# STM32L15xC register map
File version: 1.0
CPU: 
Registers are 32-bit, read-write, reset 0x0 unless marked. A register's access mark holds for its fields unless they carry their own. Offsets are from the block's base; [hi:lo] are bit positions; {n}, {i} and the like mark numbered series.

## SPI1 — Serial peripheral interface
Base 0x40013000
Same registers: SPI2 0x40003800, SPI3 0x40003C00
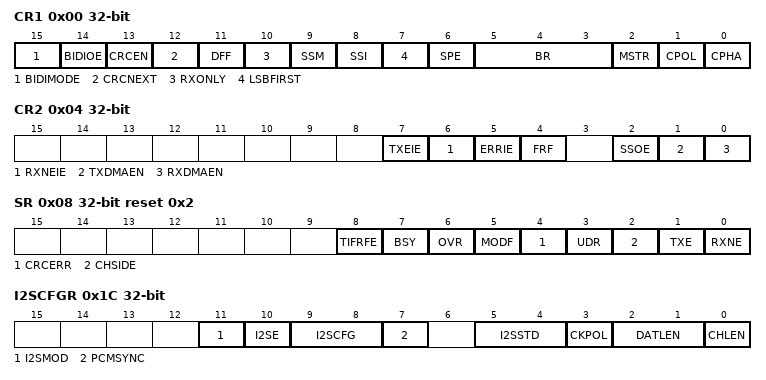
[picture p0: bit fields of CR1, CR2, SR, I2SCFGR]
0x00 CR1 — control register 1
  [15] BIDIMODE — Bidirectional data mode enable
  [14] BIDIOE — Output enable in bidirectional mode
  [13] CRCEN — Hardware CRC calculation enable
  [12] CRCNEXT — CRC transfer next
  [11] DFF — Data frame format
  [10] RXONLY — Receive only
  [9] SSM — Software slave management
  [8] SSI — Internal slave select
  [7] LSBFIRST — Frame format
  [6] SPE — SPI enable
  [5:3] BR — Baud rate control
  [2] MSTR — Master selection
  [1] CPOL — Clock polarity
  [0] CPHA — Clock phase
0x04 CR2 — control register 2
  [7] TXEIE — Tx buffer empty interrupt enable
  [6] RXNEIE — RX buffer not empty interrupt enable
  [5] ERRIE — Error interrupt enable
  [4] FRF — Frame format
  [2] SSOE — SS output enable
  [1] TXDMAEN — Tx buffer DMA enable
  [0] RXDMAEN — Rx buffer DMA enable
0x08 SR access per field reset 0x2 — status register
  [8] TIFRFE ro — TI frame format error
  [7] BSY ro — Busy flag
  [6] OVR ro — Overrun flag
  [5] MODF ro — Mode fault
  [4] CRCERR rw — CRC error flag
  [3] UDR ro — Underrun flag
  [2] CHSIDE ro — Channel side
  [1] TXE ro — Transmit buffer empty
  [0] RXNE ro — Receive buffer not empty
0x0C DR — data register
  [15:0] DR — Data register
0x10 CRCPR reset 0x7 — CRC polynomial register
  [15:0] CRCPOLY
0x14 RXCRCR ro — RX CRC register
  [15:0] RxCRC
0x18 TXCRCR ro — TX CRC register
  [15:0] TxCRC
0x1C I2SCFGR — I2S configuration register
  [11] I2SMOD — I2S mode selection
  [10] I2SE — I2S Enable
  [9:8] I2SCFG — I2S configuration mode
  [7] PCMSYNC — PCM frame synchronization
  [5:4] I2SSTD — I2S standard selection
  [3] CKPOL — Steady state clock polarity
  [2:1] DATLEN — Data length to be transferred
  [0] CHLEN — Channel length (number of bits per audio channel)
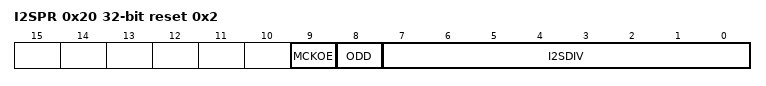
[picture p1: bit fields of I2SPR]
0x20 I2SPR reset 0x2 — I2S prescaler register
  [9] MCKOE — Master clock output enable
  [8] ODD — Odd factor for the prescaler
  [7:0] I2SDIV — I2S Linear prescaler

## SYSCFG — System configuration controller
Base 0x40010000
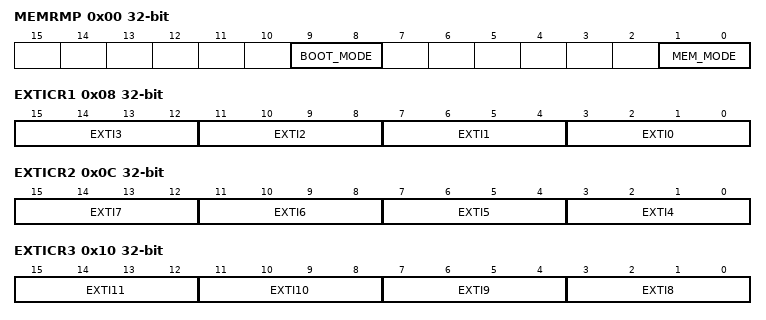
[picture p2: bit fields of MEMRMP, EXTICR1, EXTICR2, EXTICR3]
0x00 MEMRMP access per field — memory remap register
  [9:8] BOOT_MODE ro, [1:0] MEM_MODE rw
0x04 PMC — peripheral mode configuration register
  [0] USB_PU — USB pull-up
0x08 EXTICR1 — external interrupt configuration register 1
  [4n+3:4n] EXTI{n} (n=0..3) — EXTI x configuration (x = 0 to 3)
0x0C EXTICR2 — external interrupt configuration register 2
  [4n-13:4n-16] EXTI{n} (n=4..7) — EXTI x configuration (x = 4 to 7)
0x10 EXTICR3 — external interrupt configuration register 3
  [15:12] EXTI11 — EXTI x configuration (x = 8 to 11)
  [11:8] EXTI10
  [7:4] EXTI9 — EXTI x configuration (x = 8 to 11)
  [3:0] EXTI8 — EXTI x configuration (x = 8 to 11)
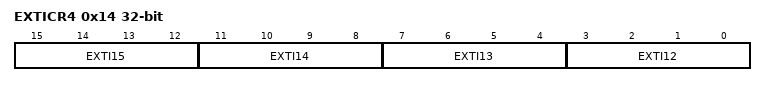
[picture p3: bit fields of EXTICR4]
0x14 EXTICR4 — external interrupt configuration register 4
  [15:12] EXTI15 — EXTI x configuration (x = 12 to 15)
  [11:8] EXTI14
  [7:4] EXTI13
  [3:0] EXTI12

## TIM10 — General-purpose timers
Base 0x40010C00
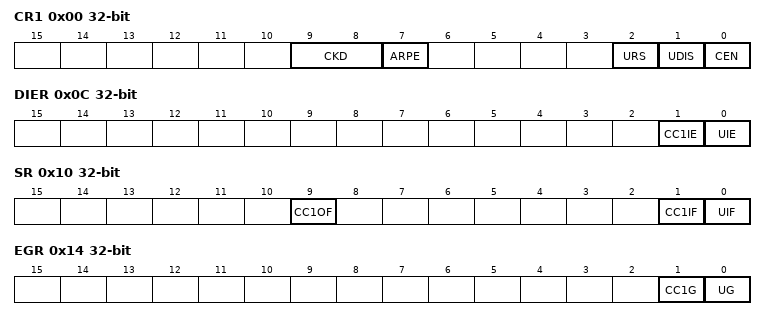
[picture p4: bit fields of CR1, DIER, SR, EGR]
0x00 CR1 — control register 1
  [9:8] CKD — Clock division
  [7] ARPE — Auto-reload preload enable
  [2] URS — Update request source
  [1] UDIS — Update disable
  [0] CEN — Counter enable
0x0C DIER wo — Interrupt enable register
  [1] CC1IE — Capture/Compare 1 interrupt enable
  [0] UIE — Update interrupt enable
0x10 SR — status register
  [9] CC1OF — Capture/compare 1 overcapture flag
  [1] CC1IF — Capture/Compare 1 interrupt flag
  [0] UIF — Update interrupt flag
0x14 EGR — event generation register
  [1] CC1G — Capture/Compare 1 generation
  [0] UG — Update generation
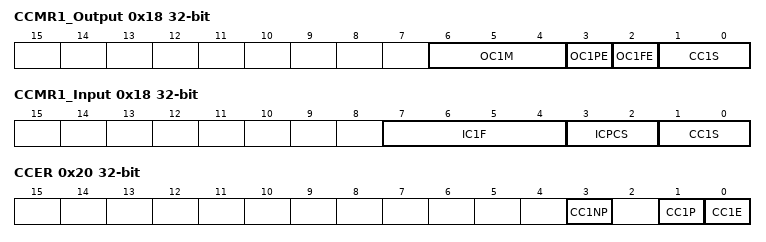
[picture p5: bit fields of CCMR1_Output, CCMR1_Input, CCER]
0x18 CCMR1_Output — capture/compare mode register
  [6:4] OC1M — Output compare 1 mode
  [3] OC1PE — Output compare 1 preload enable
  [2] OC1FE — Output compare 1 fast enable
  [1:0] CC1S — Capture/Compare 1 selection
0x18 CCMR1_Input — capture/compare mode register 1 (input mode)
  [7:4] IC1F — Input capture 1 filter
  [3:2] ICPCS — Input capture 1 prescaler
  [1:0] CC1S — Capture/Compare 1 selection
0x20 CCER — capture/compare enable register
  [3] CC1NP — Capture/Compare 1 complementary output Polarity
  [1] CC1P — Capture/Compare 1 output Polarity
  [0] CC1E — Capture/Compare 1 output enable
0x24 CNT — counter
  [15:0] CNT — TIM10 counter
0x28 PSC — prescaler
  [15:0] PSC — TIM9 prescaler
0x2C ARR — auto-reload register
  [15:0] ARR — Auto-reload value
0x34 CCR1 — capture/compare register 1
  [15:0] CCR1 — Capture/Compare 1 value
0x50 OR — option register
  [1:0] TI1_RMP — TIM11 Input 1 remapping capability

## TIM11 — General-purpose timers
Base 0x40011000
Registers as TIM10; these are added or differ:
0x24 CNT — counter
  [15:0] CNT — TIM10 counter
0x50 OR — option register
  [1:0] TI1_RMP — TIM11 Input 1 remapping capability
